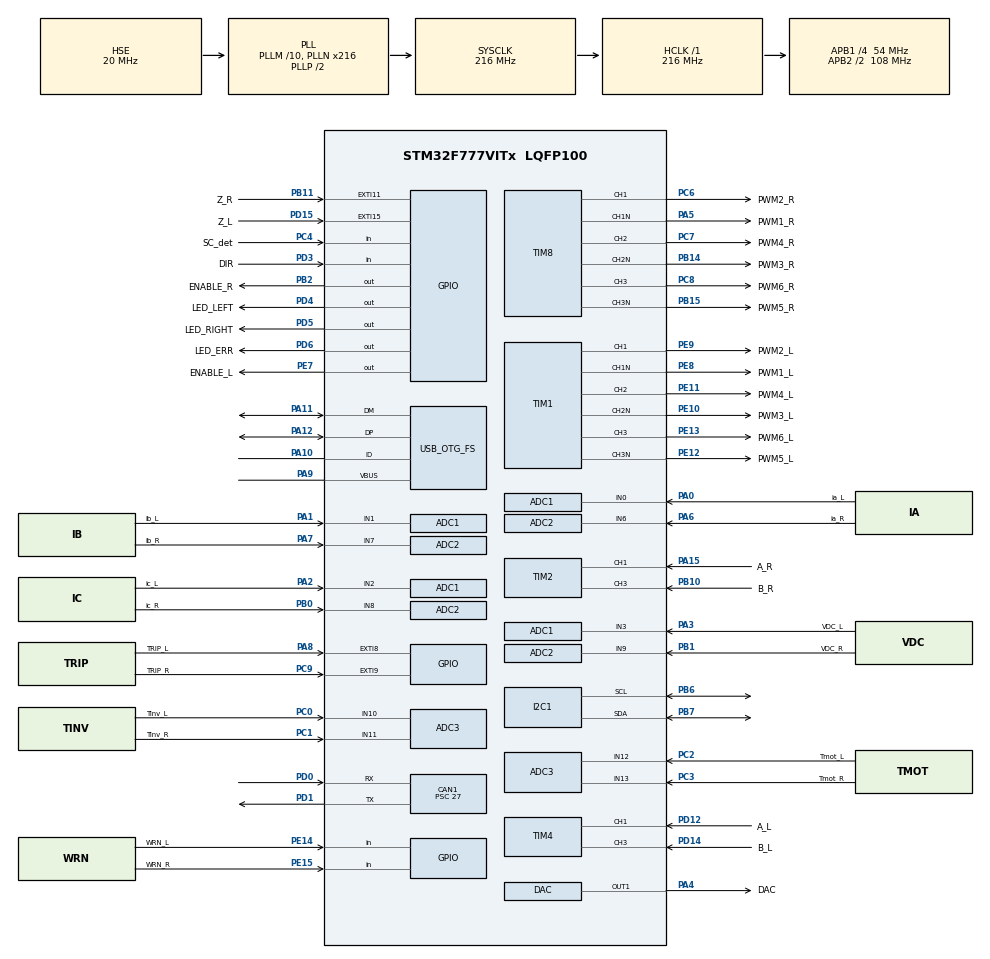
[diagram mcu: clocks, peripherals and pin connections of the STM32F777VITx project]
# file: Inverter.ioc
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ADC1.Channel-10\#ChannelRegularConversion=ADC_CHANNEL_3
ADC1.Channel-5\#ChannelRegularConversion=ADC_CHANNEL_0
ADC1.Channel-8\#ChannelRegularConversion=ADC_CHANNEL_1
ADC1.Channel-9\#ChannelRegularConversion=ADC_CHANNEL_2
ADC1.ClockPrescaler=ADC_CLOCK_SYNC_PCLK_DIV4
ADC1.ContinuousConvMode=DISABLE
ADC1.DMAContinuousRequests=ENABLE
ADC1.EOCSelection=ADC_EOC_SEQ_CONV
ADC1.ExternalTrigConv=ADC_EXTERNALTRIGCONV_T1_TRGO
ADC1.InjNumberOfConversion=0
ADC1.NbrOfConversion=4
ADC1.NbrOfConversionFlag=1
ADC1.Rank-10\#ChannelRegularConversion=4
ADC1.Rank-5\#ChannelRegularConversion=1
ADC1.Rank-8\#ChannelRegularConversion=2
ADC1.Rank-9\#ChannelRegularConversion=3
ADC1.SamplingTime-10\#ChannelRegularConversion=ADC_SAMPLETIME_3CYCLES
ADC1.SamplingTime-5\#ChannelRegularConversion=ADC_SAMPLETIME_3CYCLES
ADC1.SamplingTime-8\#ChannelRegularConversion=ADC_SAMPLETIME_3CYCLES
ADC1.SamplingTime-9\#ChannelRegularConversion=ADC_SAMPLETIME_3CYCLES
ADC1.master=1
ADC2.Channel-0\#ChannelRegularConversion=ADC_CHANNEL_6
ADC2.Channel-1\#ChannelRegularConversion=ADC_CHANNEL_7
ADC2.Channel-2\#ChannelRegularConversion=ADC_CHANNEL_8
ADC2.Channel-3\#ChannelRegularConversion=ADC_CHANNEL_9
ADC2.ClockPrescaler=ADC_CLOCK_SYNC_PCLK_DIV4
ADC2.ContinuousConvMode=DISABLE
ADC2.DMAContinuousRequests=ENABLE
ADC2.EOCSelection=ADC_EOC_SEQ_CONV
ADC2.ExternalTrigConv=ADC_EXTERNALTRIGCONV_T1_TRGO
ADC2.ExternalTrigConvEdge=ADC_EXTERNALTRIGCONVEDGE_RISING
ADC2.InjNumberOfConversion=0
ADC2.NbrOfConversion=4
ADC2.NbrOfConversionFlag=1
ADC2.Rank-0\#ChannelRegularConversion=1
ADC2.Rank-1\#ChannelRegularConversion=2
ADC2.Rank-2\#ChannelRegularConversion=3
ADC2.Rank-3\#ChannelRegularConversion=4
ADC2.SamplingTime-0\#ChannelRegularConversion=ADC_SAMPLETIME_3CYCLES
ADC2.SamplingTime-1\#ChannelRegularConversion=ADC_SAMPLETIME_3CYCLES
ADC2.SamplingTime-2\#ChannelRegularConversion=ADC_SAMPLETIME_3CYCLES
ADC2.SamplingTime-3\#ChannelRegularConversion=ADC_SAMPLETIME_3CYCLES
ADC2.ScanConvMode=ADC_SCAN_ENABLE
ADC3.Channel-0\#ChannelRegularConversion=ADC_CHANNEL_10
ADC3.Channel-1\#ChannelRegularConversion=ADC_CHANNEL_11
ADC3.Channel-2\#ChannelRegularConversion=ADC_CHANNEL_12
ADC3.Channel-3\#ChannelRegularConversion=ADC_CHANNEL_13
ADC3.ClockPrescaler=ADC_CLOCK_SYNC_PCLK_DIV4
ADC3.DMAContinuousRequests=ENABLE
ADC3.EOCSelection=ADC_EOC_SEQ_CONV
ADC3.ExternalTrigConv=ADC_EXTERNALTRIGCONV_T6_TRGO
ADC3.NbrOfConversion=4
ADC3.NbrOfConversionFlag=1
ADC3.Rank-0\#ChannelRegularConversion=1
ADC3.Rank-1\#ChannelRegularConversion=2
ADC3.Rank-2\#ChannelRegularConversion=3
ADC3.Rank-3\#ChannelRegularConversion=4
ADC3.SamplingTime-0\#ChannelRegularConversion=ADC_SAMPLETIME_56CYCLES
ADC3.SamplingTime-1\#ChannelRegularConversion=ADC_SAMPLETIME_56CYCLES
ADC3.SamplingTime-2\#ChannelRegularConversion=ADC_SAMPLETIME_56CYCLES
ADC3.SamplingTime-3\#ChannelRegularConversion=ADC_SAMPLETIME_56CYCLES
ADC3.ScanConvMode=ADC_SCAN_ENABLE
CAN1.BS1=CAN_BS1_2TQ
CAN1.CalculateBaudRate=500000
CAN1.CalculateTimeBit=2000
CAN1.CalculateTimeQuantum=500.0
CAN1.Prescaler=27
Dma.ADC1.2.Direction=DMA_PERIPH_TO_MEMORY
Dma.ADC1.2.FIFOMode=DMA_FIFOMODE_DISABLE
Dma.ADC1.2.Instance=DMA2_Stream0
Dma.ADC1.2.MemDataAlignment=DMA_MDATAALIGN_WORD
Dma.ADC1.2.MemInc=DMA_MINC_ENABLE
Dma.ADC1.2.Mode=DMA_NORMAL
Dma.ADC1.2.PeriphDataAlignment=DMA_PDATAALIGN_WORD
Dma.ADC1.2.PeriphInc=DMA_PINC_DISABLE
Dma.ADC1.2.Priority=DMA_PRIORITY_LOW
Dma.ADC2.0.Direction=DMA_PERIPH_TO_MEMORY
Dma.ADC2.0.FIFOMode=DMA_FIFOMODE_DISABLE
Dma.ADC2.0.Instance=DMA2_Stream2
Dma.ADC2.0.MemDataAlignment=DMA_MDATAALIGN_HALFWORD
Dma.ADC2.0.MemInc=DMA_MINC_ENABLE
Dma.ADC2.0.Mode=DMA_CIRCULAR
Dma.ADC2.0.PeriphDataAlignment=DMA_PDATAALIGN_HALFWORD
Dma.ADC2.0.PeriphInc=DMA_PINC_DISABLE
Dma.ADC2.0.Priority=DMA_PRIORITY_LOW
Dma.ADC3.1.Direction=DMA_PERIPH_TO_MEMORY
Dma.ADC3.1.FIFOMode=DMA_FIFOMODE_DISABLE
Dma.ADC3.1.Instance=DMA2_Stream1
Dma.ADC3.1.MemDataAlignment=DMA_MDATAALIGN_HALFWORD
Dma.ADC3.1.MemInc=DMA_MINC_ENABLE
Dma.ADC3.1.Mode=DMA_CIRCULAR
Dma.ADC3.1.PeriphDataAlignment=DMA_PDATAALIGN_HALFWORD
Dma.ADC3.1.PeriphInc=DMA_PINC_DISABLE
Dma.ADC3.1.Priority=DMA_PRIORITY_LOW
Dma.Request0=ADC2
Dma.Request1=ADC3
Dma.Request2=ADC1
I2C1.Timing=0x20404768
Mcu.Family=STM32F7
Mcu.Name=STM32F777VITx
Mcu.Package=LQFP100
NVIC.CAN1_RX0_IRQn=true\:0\:0\:false\:false\:true\:true\:true\:true
NVIC.DMA2_Stream0_IRQn=true\:0\:0\:false\:false\:true\:false\:true\:true
NVIC.DMA2_Stream1_IRQn=true\:0\:0\:false\:false\:true\:false\:true\:true
NVIC.DMA2_Stream2_IRQn=true\:0\:0\:false\:false\:true\:false\:true\:true
NVIC.PriorityGroup=NVIC_PRIORITYGROUP_4
NVIC.TIM1_UP_TIM10_IRQn=true\:0\:0\:false\:false\:true\:true\:true\:true
NVIC.TIM6_DAC_IRQn=true\:0\:0\:false\:false\:true\:false\:true\:true
PA0/WKUP.GPIO_Label=ia_L
PA0/WKUP.Signal=ADCx_IN0
PA1.GPIO_Label=ib_L
PA1.Signal=ADCx_IN1
PA10.Mode=OTG/Dual_Role_Device
PA10.Signal=USB_OTG_FS_ID
PA11.Mode=OTG/Dual_Role_Device
PA11.Signal=USB_OTG_FS_DM
PA12.Mode=OTG/Dual_Role_Device
PA12.Signal=USB_OTG_FS_DP
PA13.Mode=Trace_Asynchronous_SW
PA13.Signal=SYS_JTMS-SWDIO
PA14.Mode=Trace_Asynchronous_SW
PA14.Signal=SYS_JTCK-SWCLK
PA15.GPIO_Label=A_R
PA15.Signal=S_TIM2_CH1_ETR
PA2.GPIO_Label=ic_L
PA2.Signal=ADCx_IN2
PA3.GPIO_Label=VDC_L
PA3.Signal=ADCx_IN3
PA4.GPIO_Label=DAC
PA4.Signal=COMP_DAC1_group
PA5.GPIO_Label=PWM1_R
PA5.Mode=PWM Generation1 CH1 CH1N
PA5.Signal=TIM8_CH1N
PA6.GPIO_Label=ia_R
PA6.Signal=ADCx_IN6
PA7.GPIO_Label=ib_R
PA7.Signal=ADCx_IN7
PA8.GPIO_Label=TRIP_L
PA8.Signal=GPXTI8
PA9.Mode=Activate_VBUS
PA9.Signal=USB_OTG_FS_VBUS
PB0.GPIO_Label=ic_R
PB0.Signal=ADCx_IN8
PB1.GPIO_Label=VDC_R
PB1.Signal=ADCx_IN9
PB10.GPIO_Label=B_R
PB10.Signal=S_TIM2_CH3
PB11.GPIO_Label=Z_R
PB11.Signal=GPXTI11
PB14.GPIO_Label=PWM3_R
PB14.Mode=PWM Generation2 CH2 CH2N
PB14.Signal=TIM8_CH2N
PB15.GPIO_Label=PWM5_R
PB15.Mode=Output Compare3 CH3 CH3N
PB15.Signal=TIM8_CH3N
PB2.GPIO_Label=ENABLE_R
PB2.Signal=GPIO_Output
PB3.Mode=Trace_Asynchronous_SW
PB3.Signal=SYS_JTDO-SWO
PB6.Mode=I2C
PB6.Signal=I2C1_SCL
PB7.Mode=I2C
PB7.Signal=I2C1_SDA
PC0.GPIO_Label=Tinv_L
PC0.Signal=ADCx_IN10
PC1.GPIO_Label=Tinv_R
PC1.Signal=ADCx_IN11
PC2.GPIO_Label=Tmot_L
PC2.Signal=ADCx_IN12
PC3.GPIO_Label=Tmot_R
PC3.Signal=ADCx_IN13
PC4.GPIO_Label=SC_det
PC4.Signal=GPIO_Input
PC6.GPIO_Label=PWM2_R
PC6.Signal=S_TIM8_CH1
PC7.GPIO_Label=PWM4_R
PC7.Signal=S_TIM8_CH2
PC8.GPIO_Label=PWM6_R
PC8.Signal=S_TIM8_CH3
PC9.GPIO_Label=TRIP_R
PC9.Signal=GPXTI9
PD0.Mode=CAN_Activate
PD0.Signal=CAN1_RX
PD1.Mode=CAN_Activate
PD1.Signal=CAN1_TX
PD12.GPIO_Label=A_L
PD12.Signal=S_TIM4_CH1
PD14.GPIO_Label=B_L
PD14.Signal=S_TIM4_CH3
PD15.GPIO_Label=Z_L
PD15.Signal=GPXTI15
PD3.GPIO_Label=DIR
PD3.GPIO_PuPd=GPIO_NOPULL
PD3.Signal=GPIO_Input
PD4.GPIO_Label=LED_LEFT
PD4.PinState=GPIO_PIN_RESET
PD4.Signal=GPIO_Output
PD5.GPIO_Label=LED_RIGHT
PD5.GPIO_ModeDefaultOutputPP=GPIO_MODE_OUTPUT_PP
PD5.GPIO_PuPd=GPIO_NOPULL
PD5.GPIO_Speed=GPIO_SPEED_FREQ_LOW
PD5.PinState=GPIO_PIN_RESET
PD5.Signal=GPIO_Output
PD6.GPIO_Label=LED_ERR
PD6.GPIO_ModeDefaultOutputPP=GPIO_MODE_OUTPUT_PP
PD6.GPIO_PuPd=GPIO_PULLDOWN
PD6.GPIO_Speed=GPIO_SPEED_FREQ_LOW
PD6.PinState=GPIO_PIN_RESET
PD6.Signal=GPIO_Output
PE10.GPIO_Label=PWM3_L
PE10.Mode=PWM Generation2 CH2 CH2N
PE10.Signal=TIM1_CH2N
PE11.GPIO_Label=PWM4_L
PE11.Signal=S_TIM1_CH2
PE12.GPIO_Label=PWM5_L
PE12.Mode=PWM Generation3 CH3 CH3N
PE12.Signal=TIM1_CH3N
PE13.GPIO_Label=PWM6_L
PE13.Signal=S_TIM1_CH3
PE14.GPIO_Label=WRN_L
PE14.Signal=GPIO_Input
PE15.GPIO_Label=WRN_R
PE15.Signal=GPIO_Input
PE7.GPIO_Label=ENABLE_L
PE7.Signal=GPIO_Output
PE8.GPIO_Label=PWM1_L
PE8.Mode=PWM Generation1 CH1 CH1N
PE8.Signal=TIM1_CH1N
PE9.GPIO_Label=PWM2_L
PE9.Signal=S_TIM1_CH1
PH0/OSC_IN.Mode=HSE-External-Oscillator
PH0/OSC_IN.Signal=RCC_OSC_IN
PH1/OSC_OUT.Mode=HSE-External-Oscillator
PH1/OSC_OUT.Signal=RCC_OSC_OUT
ProjectManager.HeapSize=0x200
ProjectManager.StackSize=0x400
ProjectManager.TargetToolchain=STM32CubeIDE
RCC.AHBFreq_Value=216000000
RCC.APB1CLKDivider=RCC_HCLK_DIV4
RCC.APB1Freq_Value=54000000
RCC.APB1TimFreq_Value=108000000
RCC.APB2CLKDivider=RCC_HCLK_DIV2
RCC.APB2Freq_Value=108000000
RCC.APB2TimFreq_Value=216000000
RCC.CortexFreq_Value=216000000
RCC.HCLKFreq_Value=216000000
RCC.HSE_VALUE=20000000
RCC.HSI_VALUE=16000000
RCC.LSE_VALUE=32768
RCC.PLLM=10
RCC.PLLN=216
RCC.PLLQ=9
RCC.SYSCLKFreq_VALUE=216000000
RCC.SYSCLKSource=RCC_SYSCLKSOURCE_PLLCLK
RCC.USBFreq_Value=48000000
RCC.VCOOutputFreq_Value=432000000
SH.ADCx_IN0.0=ADC1_IN0,IN0
SH.ADCx_IN1.0=ADC1_IN1,IN1
SH.ADCx_IN10.0=ADC3_IN10,IN10
SH.ADCx_IN11.0=ADC3_IN11,IN11
SH.ADCx_IN12.0=ADC3_IN12,IN12
SH.ADCx_IN13.0=ADC3_IN13,IN13
SH.ADCx_IN2.0=ADC1_IN2,IN2
SH.ADCx_IN3.0=ADC1_IN3,IN3
SH.ADCx_IN6.0=ADC2_IN6,IN6
SH.ADCx_IN7.0=ADC2_IN7,IN7
SH.ADCx_IN8.0=ADC2_IN8,IN8
SH.ADCx_IN9.0=ADC2_IN9,IN9
SH.COMP_DAC1_group.0=DAC_OUT1,DAC_OUT1
SH.S_TIM1_CH1.0=TIM1_CH1,PWM Generation1 CH1 CH1N
SH.S_TIM1_CH2.0=TIM1_CH2,PWM Generation2 CH2 CH2N
SH.S_TIM1_CH3.0=TIM1_CH3,PWM Generation3 CH3 CH3N
SH.S_TIM2_CH1_ETR.0=TIM2_CH1,Input_Capture1_from_TI1
SH.S_TIM2_CH3.0=TIM2_CH3,Input_Capture3_from_TI3
SH.S_TIM4_CH1.0=TIM4_CH1,Input_Capture1_from_TI1
SH.S_TIM4_CH3.0=TIM4_CH3,Input_Capture3_from_TI3
SH.S_TIM8_CH1.0=TIM8_CH1,PWM Generation1 CH1 CH1N
SH.S_TIM8_CH2.0=TIM8_CH2,PWM Generation2 CH2 CH2N
SH.S_TIM8_CH3.0=TIM8_CH3,Output Compare3 CH3 CH3N
TIM1.AutoReloadPreload=TIM_AUTORELOAD_PRELOAD_ENABLE
TIM1.Break2Filter=0
TIM1.Break2State=TIM_BREAK2_ENABLE
TIM1.Channel-PWM\ Generation1\ CH1\ CH1N=TIM_CHANNEL_1
TIM1.Channel-PWM\ Generation2\ CH2\ CH2N=TIM_CHANNEL_2
TIM1.Channel-PWM\ Generation3\ CH3\ CH3N=TIM_CHANNEL_3
TIM1.CounterMode=TIM_COUNTERMODE_CENTERALIGNED1
TIM1.DeadTime=DT*216000000
TIM1.LockLevel=TIM_LOCKLEVEL_1
TIM1.OCFastMode_PWM-PWM\ Generation1\ CH1\ CH1N=TIM_OCFAST_DISABLE
TIM1.OCIdleState_1=TIM_OCIDLESTATE_RESET
TIM1.OCIdleState_2=TIM_OCIDLESTATE_RESET
TIM1.OCIdleState_3=TIM_OCIDLESTATE_RESET
TIM1.OCNIdleState_1=TIM_OCNIDLESTATE_SET
TIM1.OCNIdleState_2=TIM_OCNIDLESTATE_SET
TIM1.OCNIdleState_3=TIM_OCNIDLESTATE_SET
TIM1.OCNPolarity_1=TIM_OCNPOLARITY_LOW
TIM1.OCNPolarity_2=TIM_OCNPOLARITY_LOW
TIM1.OCNPolarity_3=TIM_OCNPOLARITY_LOW
TIM1.OCPolarity_1=TIM_OCPOLARITY_HIGH
TIM1.OCPolarity_2=TIM_OCPOLARITY_HIGH
TIM1.OCPolarity_3=TIM_OCPOLARITY_HIGH
TIM1.OffStateIDLEMode=TIM_OSSI_ENABLE
TIM1.OffStateRunMode=TIM_OSSR_ENABLE
TIM1.Period=(216000000*TS)/2
TIM1.Pulse-PWM\ Generation1\ CH1\ CH1N=0
TIM1.Pulse-PWM\ Generation2\ CH2\ CH2N=0
TIM1.Pulse-PWM\ Generation3\ CH3\ CH3N=0
TIM1.RepetitionCounter=1
TIM1.TIM_MasterOutputTrigger=TIM_TRGO_UPDATE
TIM2.Channel-Input_Capture1_from_TI1=TIM_CHANNEL_1
TIM2.Channel-Input_Capture3_from_TI3=TIM_CHANNEL_3
TIM4.Channel-Input_Capture1_from_TI1=TIM_CHANNEL_1
TIM4.Channel-Input_Capture3_from_TI3=TIM_CHANNEL_3
TIM6.AutoReloadPreload=TIM_AUTORELOAD_PRELOAD_ENABLE
TIM6.Period=53999
TIM6.Prescaler=1
TIM6.TIM_MasterOutputTrigger=TIM_TRGO_UPDATE
TIM8.Channel-Output\ Compare3\ CH3\ CH3N=TIM_CHANNEL_3
TIM8.Channel-PWM\ Generation1\ CH1\ CH1N=TIM_CHANNEL_1
TIM8.Channel-PWM\ Generation2\ CH2\ CH2N=TIM_CHANNEL_2
VP_TIM1_VS_ClockSourceINT.Mode=Internal
VP_TIM6_VS_ClockSourceINT.Mode=Enable_Timer
VP_TIM8_VS_ClockSourceINT.Mode=Internal
board=custom

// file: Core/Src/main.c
/* USER CODE BEGIN Header */
/**
  ******************************************************************************
  * @file           : main.c
  * @brief          : Main program body
  ******************************************************************************
  * @attention
  *
  * Copyright (c) 2023 STMicroelectronics.
  * All rights reserved.
  *
  * This software is licensed under terms that can be found in the LICENSE file
  * in the root directory of this software component.
  * If no LICENSE file comes with this software, it is provided AS-IS.
  *
  ******************************************************************************
  */
/* USER CODE END Header */
#include "main.h"
#include "adc.h"
#include "can.h"
#include "dac.h"
#include "dma.h"
#include "i2c.h"
#include "tim.h"
#include "usb_otg.h"
#include "gpio.h"

/* USER CODE BEGIN Includes */
#include "FSM.h" // needs eval_inv_FSM()
#include "INVERTER.h" // needs initialize_inverter()

/* USER CODE END Includes */

void SystemClock_Config(void);

int main(void)
{

  /* MCU Configuration--------------------------------------------------------*/

  /* Reset of all peripherals, Initializes the Flash interface and the Systick. */
  HAL_Init();

  /* Configure the system clock */
  SystemClock_Config();

  /* Initialize all configured peripherals */
  MX_GPIO_Init();
  MX_DMA_Init();
  MX_ADC1_Init();
  MX_CAN1_Init();
  MX_USB_OTG_FS_USB_Init();
  MX_ADC2_Init();
  MX_ADC3_Init();
  MX_DAC_Init();
  MX_I2C1_Init();
  MX_TIM1_Init();
  MX_TIM8_Init();
  MX_TIM2_Init();
  MX_TIM4_Init();
  MX_TIM6_Init();
  /* USER CODE BEGIN 2 */

  // Initialize ADCs
  HAL_ADC_Start_DMA(&hadc3, (uint32_t *) rawADC_temp,4); // Starts ADC DMA for temperatures

  // Initialize inverters
  initialize_inverter(&inverter_left, &led_left, ENABLE_L_GPIO_Port, ENABLE_L_Pin, &htim1, &hadc2, &motor_left, rawADC_left);
  initialize_inverter(&inverter_right, &led_right, ENABLE_R_GPIO_Port, ENABLE_R_Pin, &htim8, &hadc1, &motor_right, rawADC_right);

  // Initialize 1ms timer
  HAL_TIM_Base_Start_IT(&htim6);

  HAL_CAN_Start(&hcan1);
  HAL_CAN_ActivateNotification(&hcan1, CAN_IT_RX_FIFO0_MSG_PENDING);

  /* USER CODE END 2 */

  /* Infinite loop */
  /* USER CODE BEGIN WHILE */
  while (1)
  {

      // Run FSM for left inverter
	  eval_inv_FSM(&inverter_left);

      // Run FSM for right inverter
	  eval_inv_FSM(&inverter_right);

    /* USER CODE END WHILE */

  }
}

void SystemClock_Config(void)
{
  RCC_OscInitTypeDef RCC_OscInitStruct = {0};
  RCC_ClkInitTypeDef RCC_ClkInitStruct = {0};

  /** Configure the main internal regulator output voltage
  */
  __HAL_RCC_PWR_CLK_ENABLE();
  __HAL_PWR_VOLTAGESCALING_CONFIG(PWR_REGULATOR_VOLTAGE_SCALE1);

  /** Initializes the RCC Oscillators according to the specified parameters
  * in the RCC_OscInitTypeDef structure.
  */
  RCC_OscInitStruct.OscillatorType = RCC_OSCILLATORTYPE_HSE;
  RCC_OscInitStruct.HSEState = RCC_HSE_ON;
  RCC_OscInitStruct.PLL.PLLState = RCC_PLL_ON;
  RCC_OscInitStruct.PLL.PLLSource = RCC_PLLSOURCE_HSE;
  RCC_OscInitStruct.PLL.PLLM = 10;
  RCC_OscInitStruct.PLL.PLLN = 216;
  RCC_OscInitStruct.PLL.PLLP = RCC_PLLP_DIV2;
  RCC_OscInitStruct.PLL.PLLQ = 9;
  RCC_OscInitStruct.PLL.PLLR = 2;
  if (HAL_RCC_OscConfig(&RCC_OscInitStruct) != HAL_OK)
  {
    Error_Handler();
  }

  /** Activate the Over-Drive mode
  */
  if (HAL_PWREx_EnableOverDrive() != HAL_OK)
  {
    Error_Handler();
  }

  /** Initializes the CPU, AHB and APB buses clocks
  */
  RCC_ClkInitStruct.ClockType = RCC_CLOCKTYPE_HCLK|RCC_CLOCKTYPE_SYSCLK
                              |RCC_CLOCKTYPE_PCLK1|RCC_CLOCKTYPE_PCLK2;
  RCC_ClkInitStruct.SYSCLKSource = RCC_SYSCLKSOURCE_PLLCLK;
  RCC_ClkInitStruct.AHBCLKDivider = RCC_SYSCLK_DIV1;
  RCC_ClkInitStruct.APB1CLKDivider = RCC_HCLK_DIV4;
  RCC_ClkInitStruct.APB2CLKDivider = RCC_HCLK_DIV2;

  if (HAL_RCC_ClockConfig(&RCC_ClkInitStruct, FLASH_LATENCY_7) != HAL_OK)
  {
    Error_Handler();
  }
}

void Error_Handler(void)
{
  __disable_irq();
  while (1)
  {
  }
}
